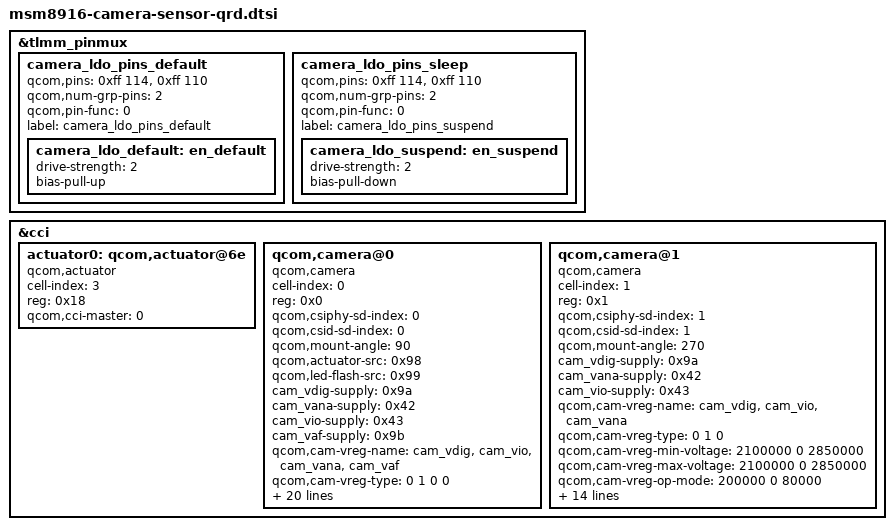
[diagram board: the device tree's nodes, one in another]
/*
 * Copyright (c) 2014, The Linux Foundation. All rights reserved.
 *
 * This program is free software; you can redistribute it and/or modify
 * it under the terms of the GNU General Public License version 2 and
 * only version 2 as published by the Free Software Foundation.
 *
 * This program is distributed in the hope that it will be useful,
 * but WITHOUT ANY WARRANTY; without even the implied warranty of
 * MERCHANTABILITY or FITNESS FOR A PARTICULAR PURPOSE.  See the
 * GNU General Public License for more details.
 */
&tlmm_pinmux {
	camera_ldo_pins_default {
		qcom,pins = <0xff 114>, <0xff 110>;
		qcom,num-grp-pins = <2>;
		qcom,pin-func = <0>;
		label = "camera_ldo_pins_default";
		camera_ldo_default: en_default {
			drive-strength = <2>;
			bias-pull-up;
		};
	};

	camera_ldo_pins_sleep {
		qcom,pins = <0xff 114>, <0xff 110>;
		qcom,num-grp-pins = <2>;
		qcom,pin-func = <0>;
		label = "camera_ldo_pins_suspend";
		camera_ldo_suspend: en_suspend {
			drive-strength = <2>;
			bias-pull-down;
		};
	};
};

&cci {
	actuator0: qcom,actuator@6e {
		cell-index = <3>;
		reg = <0x18>;
		compatible = "qcom,actuator";
		qcom,cci-master = <0>;
	};

	qcom,camera@0 {
		cell-index = <0>;
		compatible = "qcom,camera";
		reg = <0x0>;
		qcom,csiphy-sd-index = <0>;
		qcom,csid-sd-index = <0>;
		qcom,mount-angle = <90>;
		qcom,actuator-src = <0x98>;
		qcom,led-flash-src = <0x99>;
		cam_vdig-supply = <0x9a>;
		cam_vana-supply = <0x42>;
		cam_vio-supply = <0x43>;
		cam_vaf-supply = <0x9b>;
		qcom,cam-vreg-name = "cam_vdig", "cam_vio", "cam_vana",
							"cam_vaf";
		qcom,cam-vreg-type = <0 1 0 0>;
		qcom,cam-vreg-min-voltage = <2100000 0 2850000 2800000>;
		qcom,cam-vreg-max-voltage = <2100000 0 2850000 2800000>;
		qcom,cam-vreg-op-mode = <200000 0 80000 100000>;

		pinctrl-names = "cam_default", "cam_suspend";
		pinctrl-0 = <0x9c 0x9d 0x9e>;
		pinctrl-1 = <0x9f 0xa0 0xa1>;
		gpios = <0x48 0x1a 0x0 0x48 0x23 0x0 0x48 0x22 0x0 0x48 0x78 0x0>;
		qcom,gpio-reset = <1>;
		qcom,gpio-standby = <2>;
		qcom,gpio-af-pwdm = <3>;
		qcom,gpio-req-tbl-num = <0 1 2 3>;
		qcom,gpio-req-tbl-flags = <1 0 0 0>;
		qcom,gpio-req-tbl-label = "CAMIF_MCLK",
				"CAM_RESET1",
				"CAM_STANDBY",
				"CAM_AF_PWDM";
		qcom,sensor-position = <0>;
		qcom,sensor-mode = <0>;
		qcom,cci-master = <0>;
		status = "ok";
		clocks = <0x39 0x266b3853 0x39 0x80902deb>;
		clock-names = "cam_src_clk", "cam_clk";
	};

	qcom,camera@1 {
		cell-index = <1>;
		compatible = "qcom,camera";
		reg = <0x1>;
		qcom,csiphy-sd-index = <1>;
		qcom,csid-sd-index = <1>;
		qcom,mount-angle = <270>;

		cam_vdig-supply = <0x9a>;
		cam_vana-supply = <0x42>;
		cam_vio-supply = <0x43>;
		qcom,cam-vreg-name = "cam_vdig", "cam_vio", "cam_vana";
		qcom,cam-vreg-type = <0 1 0>;
		qcom,cam-vreg-min-voltage = <2100000 0 2850000>;
		qcom,cam-vreg-max-voltage = <2100000 0 2850000>;
		qcom,cam-vreg-op-mode = <200000 0 80000>;

		pinctrl-names = "cam_default", "cam_suspend";
		pinctrl-0 = <0xa2 0xa3 0x9e>;
		pinctrl-1 = <0xa4 0xa5 0xa1>;
		gpios = <0x48 0x1b 0x0 0x48 0x1c 0x0 0x48 0x21 0x0>;
		qcom,gpio-reset = <1>;
		qcom,gpio-standby = <2>;
		qcom,gpio-req-tbl-num = <0 1 2>;
		qcom,gpio-req-tbl-flags = <1 0 0>;
		qcom,gpio-req-tbl-label = "CAMIF_MCLK",
				"CAM_RESET",
				"CAM_STANDBY";
		qcom,sensor-position = <1>;
		qcom,sensor-mode = <0>;
		qcom,cci-master = <0>;
		status = "ok";
		clocks = <0x39 0xa73cad0c 0x39 0x5002d85f>;
		clock-names = "cam_src_clk", "cam_clk";
	};
};


